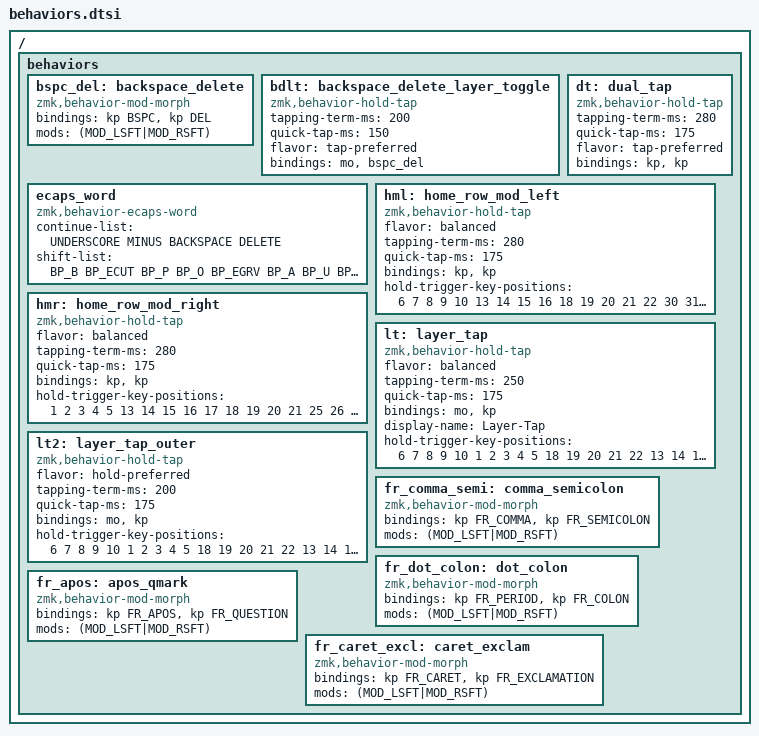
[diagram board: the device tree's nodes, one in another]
/ {
    behaviors {
        bspc_del: backspace_delete {
            compatible = "zmk,behavior-mod-morph";
            #binding-cells = <0>;
            bindings = <&kp BSPC>, <&kp DEL>;
            mods = <(MOD_LSFT|MOD_RSFT)>;
        };
        bdlt: backspace_delete_layer_toggle {
            compatible = "zmk,behavior-hold-tap";
            #binding-cells = <2>;
            tapping-term-ms = <200>;
            quick-tap-ms = <150>;
            flavor = "tap-preferred";
            bindings = <&mo>, <&bspc_del>;
        };
        ecaps_word: ecaps_word {
            compatible = "zmk,behavior-ecaps-word";
            #binding-cells = <0>;
            continue-list = <UNDERSCORE MINUS BACKSPACE DELETE>;
            shift-list = <
                BP_B  BP_ECUT BP_P  BP_O  BP_EGRV
                BP_A  BP_U    BP_I  BP_E  BP_COMM
                BP_AGRV BP_Y  BP_X  BP_DOT BP_K
                BP_DCRC BP_V  BP_M  BP_D  BP_L
                BP_J  BP_Z    BP_C  BP_CCED BP_T
                BP_S  BP_R    BP_N  BP_APOS BP_Q
                BP_G  BP_H    BP_F  BP_W
            >;
        };
        dt: dual_tap {
            compatible = "zmk,behavior-hold-tap";
            #binding-cells = <2>;
            tapping-term-ms = <280>;
            quick-tap-ms = <175>;
            flavor = "tap-preferred";
            bindings = <&kp>, <&kp>;
        };
        hml: home_row_mod_left {
            compatible = "zmk,behavior-hold-tap";
            #binding-cells = <2>;
            flavor = "balanced";
            tapping-term-ms = <280>;
            quick-tap-ms = <175>;
            bindings = <&kp>, <&kp>;
            hold-trigger-key-positions = < 
                6   7  8  9 10
                13 14 15 16  
                18 19 20 21 22 
                30 31 32 33 34
                      36 37 38
                      39 40 41 
            >; 
        };
        hmr: home_row_mod_right {
            compatible = "zmk,behavior-hold-tap";
            #binding-cells = <2>;
            flavor = "balanced";
            tapping-term-ms = <280>;
            quick-tap-ms = <175>;
            bindings = <&kp>, <&kp>;
            hold-trigger-key-positions = < 
                 1  2  3  4  5 
                13 14 15 16 17
                18 19 20 21 
                25 26 27 28 29
                36 37 38 
                39 40 41
            >; 
        };
        lt: layer_tap {
            compatible = "zmk,behavior-hold-tap";
            #binding-cells = <2>;
            flavor = "balanced";
            tapping-term-ms = <250>;
            quick-tap-ms = <175>;
            bindings = <&mo>, <&kp>;
            display-name = "Layer-Tap";
            hold-trigger-key-positions = <
                 6  7  8  9 10       1  2  3  4  5
                18 19 20 21 22      13 14 15 16 17
                30 31 32 33 34      25 26 27 28 29
                      39 40 41      36 37 38 
            >;
        };
        lt2: layer_tap_outer {
            compatible = "zmk,behavior-hold-tap";
            #binding-cells = <2>;
            flavor = "hold-preferred";
            tapping-term-ms = <200>;
            quick-tap-ms = <175>;
            bindings = <&mo>, <&kp>;
            hold-trigger-key-positions = <
                    6  7  8  9 10       1  2  3  4  5
                   18 19 20 21 22      13 14 15 16 17
                   30 31 32 33 34      25 26 27 28 29
                         39 40 41      36 37 38 
            >;       
        };
        fr_comma_semi: comma_semicolon {
            compatible = "zmk,behavior-mod-morph";
            #binding-cells = <0>;
            bindings = <&kp FR_COMMA>, <&kp FR_SEMICOLON>;
            mods = <(MOD_LSFT|MOD_RSFT)>;
        };
        fr_dot_colon: dot_colon {
            compatible = "zmk,behavior-mod-morph";
            #binding-cells = <0>;
            bindings = <&kp FR_PERIOD>, <&kp FR_COLON>;
            mods = <(MOD_LSFT|MOD_RSFT)>;
        };
        fr_apos: apos_qmark {
            compatible = "zmk,behavior-mod-morph";
            #binding-cells = <0>;
            bindings = <&kp FR_APOS>, <&kp FR_QUESTION>;
            mods = <(MOD_LSFT|MOD_RSFT)>;
        };
        fr_caret_excl: caret_exclam {
            compatible = "zmk,behavior-mod-morph";
            #binding-cells = <0>;
            bindings = <&kp FR_CARET>, <&kp FR_EXCLAMATION>;
            mods = <(MOD_LSFT|MOD_RSFT)>;
        };                              
    };
};
